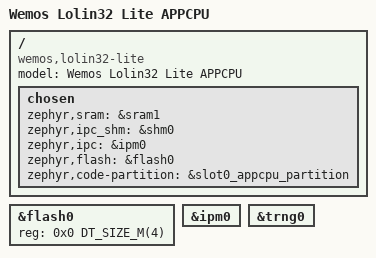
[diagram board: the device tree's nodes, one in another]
/*
 * Copyright (c) 2025 Siratul Islam <email@sirat.me>
 *
 * SPDX-License-Identifier: Apache-2.0
 */
/dts-v1/;

#include <espressif/esp32/esp32_appcpu.dtsi>
#include <espressif/partitions_0x1000_amp.dtsi>

/ {
	model = "Wemos Lolin32 Lite APPCPU";
	compatible = "wemos,lolin32-lite";

	chosen {
		zephyr,sram = &sram1;
		zephyr,ipc_shm = &shm0;
		zephyr,ipc = &ipm0;
		zephyr,flash = &flash0;
		zephyr,code-partition = &slot0_appcpu_partition;
	};
};

&flash0 {
	reg = <0x0 DT_SIZE_M(4)>;
	ranges = <0x0 0x0 DT_SIZE_M(4)>;
};

&ipm0 {
	status = "okay";
};

&trng0 {
	status = "okay";
};
